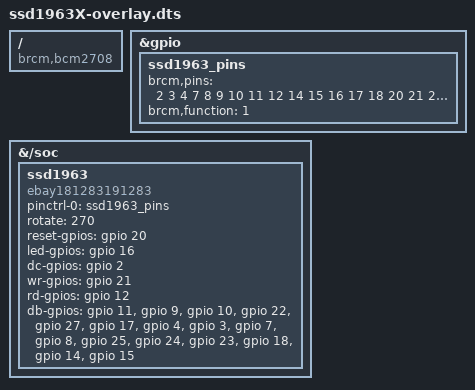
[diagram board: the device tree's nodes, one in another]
/*
 * Device Tree overlay for ssd1963 based ebay display
 *
 */

/dts-v1/;
/plugin/;

/ {
	compatible = "brcm,bcm2708";
	
	fragment@0 {
		target = <&gpio>;
		__overlay__ {
			ssd1963_pins: ssd1963_pins {
				brcm,pins = <2 3 4 7 8 9 10 11 12 14 15 16 17 18 20 21 22 23 24 25 27>;
				brcm,function = <1>; /* out */
			};
		};
	};

	fragment@1 {
		target-path = "/soc";
		__overlay__ {
			ssd1963: ssd1963 {
				compatible = "ebay181283191283";
				pinctrl-names = "default";
				pinctrl-0 = <&ssd1963_pins>;
		
				rotate = <270>;
				reset-gpios = <&gpio 20 0>;
				led-gpios = <&gpio 16 0>;
				dc-gpios = <&gpio  2 0>;
				wr-gpios = <&gpio 21 0>;
				rd-gpios = <&gpio 12 0>;
				db-gpios = <&gpio 11 0>,
					   <&gpio  9 0>,
					   <&gpio 10 0>,
					   <&gpio 22 0>,
					   <&gpio 27 0>,
					   <&gpio 17 0>,
					   <&gpio  4 0>,
					   <&gpio  3 0>,
					   <&gpio  7 0>,
					   <&gpio  8 0>,
					   <&gpio 25 0>,
					   <&gpio 24 0>,
					   <&gpio 23 0>,
					   <&gpio 18 0>,
					   <&gpio 14 0>,
					   <&gpio 15 0>;
			};
		};
	};

	__overrides__ {
		rotate =  <&ssd1963>,"rotate:0";
	};
};
